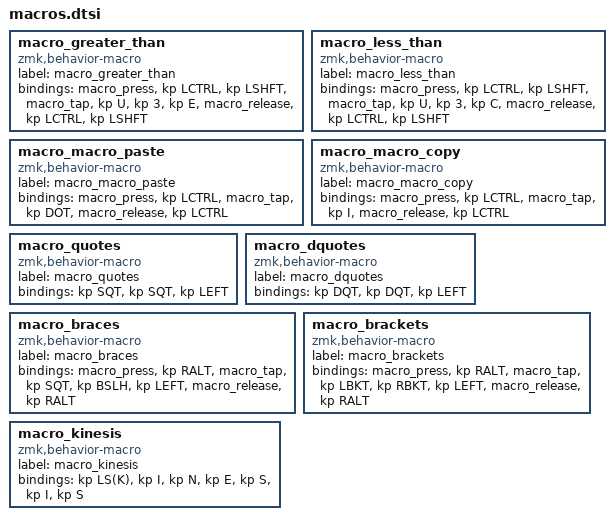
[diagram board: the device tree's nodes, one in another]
macro_greater_than: macro_greater_than{
compatible = "zmk,behavior-macro";
label = "macro_greater_than";
#binding-cells = <0>;
bindings = <&macro_press &kp LCTRL &kp LSHFT>, <&macro_tap &kp U &kp 3 &kp E>, <&macro_release &kp LCTRL &kp LSHFT>;
};
macro_less_than: macro_less_than{
compatible = "zmk,behavior-macro";
label = "macro_less_than";
#binding-cells = <0>;
bindings = <&macro_press &kp LCTRL &kp LSHFT>, <&macro_tap &kp U &kp 3 &kp C>, <&macro_release &kp LCTRL &kp LSHFT>;
};
macro_macro_paste: macro_macro_paste{
compatible = "zmk,behavior-macro";
label = "macro_macro_paste";
#binding-cells = <0>;
bindings = <&macro_press &kp LCTRL>, <&macro_tap &kp DOT>, <&macro_release &kp LCTRL>;
};
macro_macro_copy: macro_macro_copy{
compatible = "zmk,behavior-macro";
label = "macro_macro_copy";
#binding-cells = <0>;
bindings = <&macro_press &kp LCTRL>, <&macro_tap &kp I>, <&macro_release &kp LCTRL>;
};
macro_quotes: macro_quotes{
compatible = "zmk,behavior-macro";
label = "macro_quotes";
#binding-cells = <0>;
bindings = <&kp SQT>, <&kp SQT>, <&kp LEFT>;
};
macro_dquotes: macro_dquotes{
compatible = "zmk,behavior-macro";
label = "macro_dquotes";
#binding-cells = <0>;
bindings = <&kp DQT>, <&kp DQT>, <&kp LEFT>;
};
macro_braces: macro_braces{
compatible = "zmk,behavior-macro";
label = "macro_braces";
#binding-cells = <0>;
bindings = <&macro_press &kp RALT>, <&macro_tap &kp SQT &kp BSLH &kp LEFT>, <&macro_release &kp RALT>;
};
macro_brackets: macro_brackets{
compatible = "zmk,behavior-macro";
label = "macro_brackets";
#binding-cells = <0>;
bindings = <&macro_press &kp RALT>, <&macro_tap &kp LBKT &kp RBKT &kp LEFT>, <&macro_release &kp RALT>;
};
macro_kinesis: macro_kinesis{
compatible = "zmk,behavior-macro";
label = "macro_kinesis";
#binding-cells = <0>;
bindings = <&kp LS(K)>, <&kp I>, <&kp N>, <&kp E>, <&kp S>, <&kp I>, <&kp S>;
};
